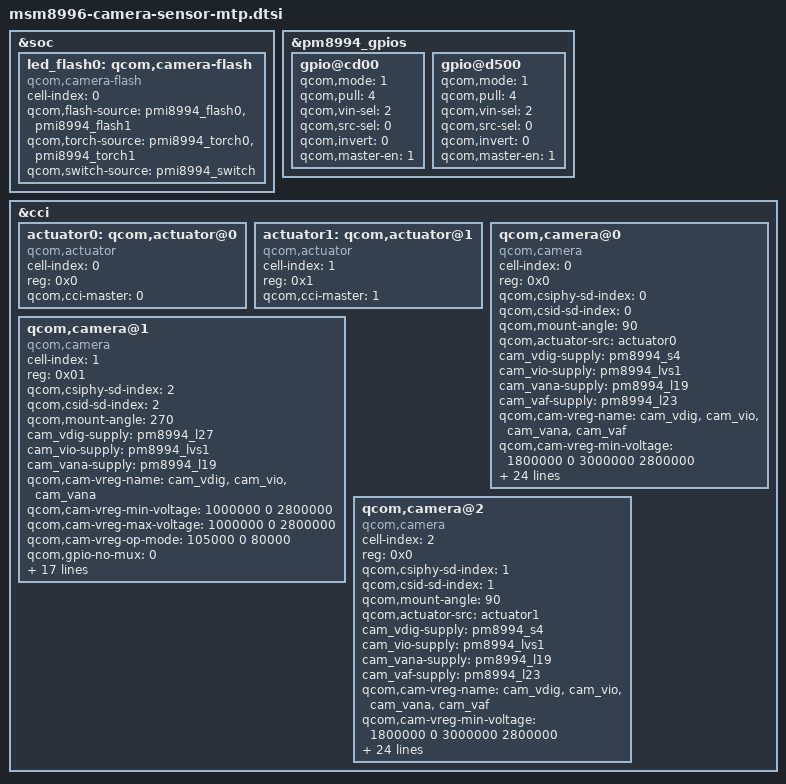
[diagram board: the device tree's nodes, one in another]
/*
 * Copyright (c) 2015 The Linux Foundation. All rights reserved.
 *
 * This program is free software; you can redistribute it and/or modify
 * it under the terms of the GNU General Public License version 2 and
 * only version 2 as published by the Free Software Foundation.
 *
 * This program is distributed in the hope that it will be useful,
 * but WITHOUT ANY WARRANTY; without even the implied warranty of
 * MERCHANTABILITY or FITNESS FOR A PARTICULAR PURPOSE.  See the
 * GNU General Public License for more details.
 */

&soc {
	led_flash0: qcom,camera-flash {
		cell-index = <0>;
		compatible = "qcom,camera-flash";
		qcom,flash-source = <&pmi8994_flash0 &pmi8994_flash1>;
		qcom,torch-source = <&pmi8994_torch0 &pmi8994_torch1>;
		qcom,switch-source = <&pmi8994_switch>;
	};
};

&pm8994_gpios {

	gpio@cd00 { /* GPIO 14 - RFARCAM_AVDD_EN */
		qcom,mode = <1>;		/* Digital output*/
		qcom,pull = <4>;		/* Pulldown 10uA */
		qcom,vin-sel = <2>;		/* VIN2 */
		qcom,src-sel = <0>;		/* GPIO */
		qcom,invert = <0>;		/* Invert */
		qcom,master-en = <1>;		/* Enable GPIO */
		status = "okay";
	};
	
	gpio@d500 { /* GPIO 22 - RFARCAM_DVDD_EN */
		qcom,mode = <1>;		/* Digital output*/
		qcom,pull = <4>;		/* Pulldown 10uA */
		qcom,vin-sel = <2>;		/* VIN2 */
		qcom,src-sel = <0>;		/* GPIO */
		qcom,invert = <0>;		/* Invert */
		qcom,master-en = <1>;		/* Enable GPIO */
		status = "okay";
	};	
};

&cci {
	actuator0: qcom,actuator@0 {
		cell-index = <0>;
		reg = <0x0>;
		compatible = "qcom,actuator";
		qcom,cci-master = <0>;
	};

	actuator1: qcom,actuator@1 {
		cell-index = <1>;
		reg = <0x1>;
		compatible = "qcom,actuator";
		qcom,cci-master = <1>;
	};

	qcom,camera@0 {
		cell-index = <0>;
		compatible = "qcom,camera";
		reg = <0x0>;
		qcom,csiphy-sd-index = <0>;
		qcom,csid-sd-index = <0>;
		qcom,mount-angle = <90>;
		//qcom,led-flash-src = <&led_flash0>;
		qcom,actuator-src = <&actuator0>;
		//qcom,eeprom-src = <&eeprom0>;
		cam_vdig-supply = <&pm8994_s4>;
		cam_vio-supply = <&pm8994_lvs1>;
		cam_vana-supply = <&pm8994_l19>;
		cam_vaf-supply = <&pm8994_l23>;
		qcom,cam-vreg-name = "cam_vdig", "cam_vio", "cam_vana", "cam_vaf";
		qcom,cam-vreg-min-voltage = <1800000 0 3000000 2800000>;
		qcom,cam-vreg-max-voltage = <1800000 0 3000000 2800000>;
		qcom,cam-vreg-op-mode = <105000 0 80000 100000>;
		qcom,gpio-no-mux = <0>;
		pinctrl-names = "cam_default", "cam_suspend";
		pinctrl-0 = <&cam_sensor_mclk0_active &cam_sensor_rear_active>;
		pinctrl-1 = <&cam_sensor_mclk0_suspend &cam_sensor_rear_suspend>;
		gpios = <&tlmm 13 0>,
			<&tlmm 30 0>,
			<&tlmm 29 0>,
			<&pm8994_gpios 22 0>,
			<&pm8994_gpios 14 0>;
			
		qcom,gpio-reset = <1>;
		qcom,gpio-standby = <2>;
		qcom,gpio-vdig = <3>;
		qcom,gpio-vana = <4>;
		qcom,gpio-req-tbl-num = <0 1 2 3 4>;
		qcom,gpio-req-tbl-flags = <1 0 0 0 0>;
		qcom,gpio-req-tbl-label = "CAMIF_MCLK0",
					  "CAM_RESET0",
					  "CAM_STANDBY0",
					  "CAM_VDIG0",
					  "CAM_VANA0";
		qcom,sensor-position = <0>;
		qcom,sensor-mode = <0>;
		qcom,cci-master = <0>;
		status = "ok";
		clocks = <&clock_mmss clk_mclk0_clk_src>,
				<&clock_mmss clk_camss_mclk0_clk>;
		clock-names = "cam_src_clk", "cam_clk";
	};
	
	qcom,camera@1 {
		cell-index = <1>;
		compatible = "qcom,camera";
		reg = <0x01>;
		qcom,csiphy-sd-index = <2>;
		qcom,csid-sd-index = <2>;
		qcom,mount-angle = <270>;
		//qcom,eeprom-src = <&eeprom1>;
		//qcom,actuator-src = <&actuator1>;
		cam_vdig-supply = <&pm8994_l27>;
		cam_vio-supply = <&pm8994_lvs1>;
		cam_vana-supply = <&pm8994_l19>;
		qcom,cam-vreg-name = "cam_vdig", "cam_vio", "cam_vana";
		qcom,cam-vreg-min-voltage = <1000000 0 2800000>;
		qcom,cam-vreg-max-voltage = <1000000 0 2800000>;
		qcom,cam-vreg-op-mode = <105000 0 80000>;
		qcom,gpio-no-mux = <0>;
		pinctrl-names = "cam_default", "cam_suspend";
		pinctrl-0 = <&cam_sensor_mclk2_active &cam_sensor_front_active>;
		pinctrl-1 = <&cam_sensor_mclk2_suspend &cam_sensor_front_suspend>;
		gpios = <&tlmm 15 0>,
			<&tlmm 23 0>,
			<&tlmm 26 0>,
			<&tlmm 80 0>;
		qcom,gpio-reset = <1>;
		qcom,gpio-standby = <2>;
		qcom,gpio-vana = <3>;
		qcom,gpio-req-tbl-num = <0 1 2 3>;
		qcom,gpio-req-tbl-flags = <1 0 0 0>;
		qcom,gpio-req-tbl-label = "CAMIF_MCLK2",
					  "CAM_RESET2",
					  "CAM_STANDBY2",
					  "CAM_VANA2";
		qcom,sensor-position = <1>;
		qcom,sensor-mode = <1>;
		qcom,cci-master = <1>;
		status = "ok";
		clocks = <&clock_mmss clk_mclk2_clk_src>,
			<&clock_mmss clk_camss_mclk2_clk>;
		clock-names = "cam_src_clk", "cam_clk";
	};
	
	qcom,camera@2 {
		cell-index = <2>;
		compatible = "qcom,camera";
		reg = <0x0>;
		qcom,csiphy-sd-index = <1>;
		qcom,csid-sd-index = <1>;
		qcom,mount-angle = <90>;
		//qcom,led-flash-src = <&led_flash0>;
		qcom,actuator-src = <&actuator1>;
		//qcom,eeprom-src = <&eeprom0>;
		cam_vdig-supply = <&pm8994_s4>;
		cam_vio-supply = <&pm8994_lvs1>;
		cam_vana-supply = <&pm8994_l19>;
		cam_vaf-supply = <&pm8994_l23>;
		qcom,cam-vreg-name = "cam_vdig", "cam_vio", "cam_vana", "cam_vaf";
		qcom,cam-vreg-min-voltage = <1800000 0 3000000 2800000>;
		qcom,cam-vreg-max-voltage = <1800000 0 3000000 2800000>;
		qcom,cam-vreg-op-mode = <105000 0 80000 100000>;
		qcom,gpio-no-mux = <0>;
		pinctrl-names = "cam_default", "cam_suspend";
		pinctrl-0 = <&cam_sensor_mclk1_active &cam_sensor_rear2_active>;
		pinctrl-1 = <&cam_sensor_mclk1_suspend &cam_sensor_rear2_suspend>;
		gpios = <&tlmm 14 0>,
			<&tlmm 85 0>,
			<&tlmm 86 0>,
			<&pm8994_gpios 22 0>,
			<&pm8994_gpios 14 0>;
			
		qcom,gpio-reset = <1>;
		qcom,gpio-standby = <2>;
		qcom,gpio-vdig = <3>;
		qcom,gpio-vana = <4>;
		qcom,gpio-req-tbl-num = <0 1 2 3 4>;
		qcom,gpio-req-tbl-flags = <1 0 0 0 0>;
		qcom,gpio-req-tbl-label = "CAMIF_MCLK1",
					  "CAM_RESET2",
					  "CAM_STANDBY2",
					  "CAM_VDIG2",
					  "CAM_VANA2";
		qcom,sensor-position = <0>;
		qcom,sensor-mode = <2>;
		qcom,cci-master = <1>;
		status = "ok";
		clocks = <&clock_mmss clk_mclk1_clk_src>,
				<&clock_mmss clk_camss_mclk1_clk>;
		clock-names = "cam_src_clk", "cam_clk";
	};
	
};
